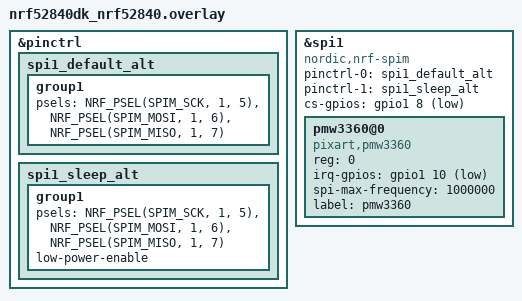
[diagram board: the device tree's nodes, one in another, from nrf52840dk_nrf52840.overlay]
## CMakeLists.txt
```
# Copyright (c) 2021 Teslabs Engineering S.L.
# SPDX-License-Identifier: Apache-2.0

cmake_minimum_required(VERSION 3.20.0)
find_package(Zephyr REQUIRED HINTS $ENV{ZEPHYR_BASE})
project(pmw3360)

FILE(GLOB app_sources src/*.c)
target_sources(app PRIVATE ${app_sources})
```

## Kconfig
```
source "Kconfig.zephyr"

menu "PMW3360"

config PMW3360_MOTION 
	bool "Enable PMW3360 motion pin interrupt trigger"
	default n

endmenu
```

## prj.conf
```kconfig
CONFIG_LOG=y
CONFIG_SPI_LOG_LEVEL_INF=y
CONFIG_PMW3360_LOG_LEVEL_DBG=y

CONFIG_CBPRINTF_FP_SUPPORT=y

CONFIG_SPI=y
CONFIG_SENSOR=y

CONFIG_PMW3360=y
# CONFIG_PMW3360_ORIENTATION_0=y
# CONFIG_PMW3360_CPI=1600
# CONFIG_PMW3360_RUN_DOWNSHIFT_TIME_MS=500
# CONFIG_PMW3360_REST1_DOWNSHIFT_TIME_MS=500
# CONFIG_PMW3360_REST2_DOWNSHIFT_TIME_MS=500

CONFIG_PMW3360_MOTION=n
```

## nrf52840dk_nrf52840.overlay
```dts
&pinctrl {
	spi1_default_alt: spi1_default_alt{
		group1{
      psels = <NRF_PSEL(SPIM_SCK, 1, 5)>,
              <NRF_PSEL(SPIM_MOSI, 1, 6)>,
              <NRF_PSEL(SPIM_MISO, 1, 7)>;
		};
	};
	spi1_sleep_alt: spi1_sleep_alt{
		group1{
      psels = <NRF_PSEL(SPIM_SCK, 1, 5)>,
              <NRF_PSEL(SPIM_MOSI, 1, 6)>,
              <NRF_PSEL(SPIM_MISO, 1, 7)>;
			low-power-enable;
		};
	};
};

&spi1 {
  compatible = "nordic,nrf-spim";
  status = "okay";
  pinctrl-0 = <&spi1_default_alt>;
  pinctrl-1 = <&spi1_sleep_alt>;
  pinctrl-names = "default", "sleep";
  cs-gpios = <&gpio1 8 GPIO_ACTIVE_LOW>;

  pmw3360@0 {
    compatible = "pixart,pmw3360";
    reg = <0>;
    irq-gpios = <&gpio1 10 GPIO_ACTIVE_LOW>;
    spi-max-frequency = <1000000>;
    label = "pmw3360";
  };
};

// &uart0_default {
// 	group1 {
// 		psels = <NRF_PSEL(UART_TX, 0, 29)>, <NRF_PSEL(UART_RX, 0, 31)>;
// 	};
// };

// &uart0_sleep {
// 	group1 {
// 		psels = <NRF_PSEL(UART_TX, 0, 29)>, <NRF_PSEL(UART_RX, 0, 31)>;
// 	};
// };
```

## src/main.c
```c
/*
 * Copyright (c) 2021 Teslabs Engineering S.L.
 *
 * SPDX-License-Identifier: Apache-2.0
 */

/* Ref: https://developer.nordicsemi.com/nRF_Connect_SDK/doc/2.1.2/nrf/drivers/pmw3360.html. */

#include <stdio.h>
#include <zephyr/zephyr.h>
#include <zephyr/device.h>
#include <zephyr/drivers/sensor.h>

const struct device *pmw3360 = DEVICE_DT_GET_ONE(pixart_pmw3360);

static struct sensor_trigger pmw3360_trigger = {
    .type = SENSOR_TRIG_DATA_READY,
    .chan = SENSOR_CHAN_ALL,
};

/**
 * @brief Read X/Y value from PMW3360.
 *
 * @param dev PMW3360
 * @param x X axis value.
 * @param y Y axis value.
 * @return 0 if successful, otherwise error code.
 */
static int read_pmw3360(const struct device *dev, int *x, int *y)
{
  *x = 0;
  *y = 0;
  struct sensor_value sen_x;
  struct sensor_value sen_y;
  int ret;

  ret = sensor_sample_fetch_chan(dev, SENSOR_CHAN_ALL);
  if (ret < 0)
  {
    printf("Could not fetch (%d)\n", ret);
    return ret;
  }

  ret = sensor_channel_get(dev, SENSOR_CHAN_POS_DX, &sen_x);
  if (ret < 0)
  {
    printf("Could not get value X (%d)\n", ret);
    return ret;
  }

  ret = sensor_channel_get(dev, SENSOR_CHAN_POS_DY, &sen_y);
  if (ret < 0)
  {
    printf("Could not get value Y (%d)\n", ret);
    return ret;
  }

  *x = sen_x.val1;
  *y = sen_y.val1;
  return 0; /* Successful. */
}

static void pmw3360_trg_handler(const struct device *dev, const struct sensor_trigger *trig)
{
  int x;
  int y;
  int rec = read_pmw3360(dev, &x, &y);
  if (rec != 0)
  {
    printf("Trigger fail (%d)", rec);
    (void)sensor_trigger_set(dev, trig, NULL);
    return;
  }

  printf("X: %5d, Y: %5d \n", x, y);
}

void main(void)
{
  if (!device_is_ready(pmw3360))
  {
    printk("sensor: device %s not ready.\n", pmw3360->name);
    return;
  }

  printk("PMW3360 is ready.\n");
  k_sleep(K_MSEC(1500));

#if defined(CONFIG_PMW3360_MOTION)

  int rec = sensor_trigger_set(pmw3360, &pmw3360_trigger, pmw3360_trg_handler);
  if (rec != 0)
  {
    printf("Cannot config trigger (%d)", rec);
    return;
  }

  while (1)
  {
    k_sleep(K_MSEC(1000));
  }

#else

  while (1)
  {
    int x;
    int y;
    int ret = read_pmw3360(pmw3360, &x, &y);
    if (ret != 0)
    {
      printf("Cannot get value (%d)", ret);
      continue;
    }

    printf("X: %6d, Y: %6d \n", x, y);
    k_sleep(K_MSEC(500)); /* Delay */
  }

#endif
}
```
